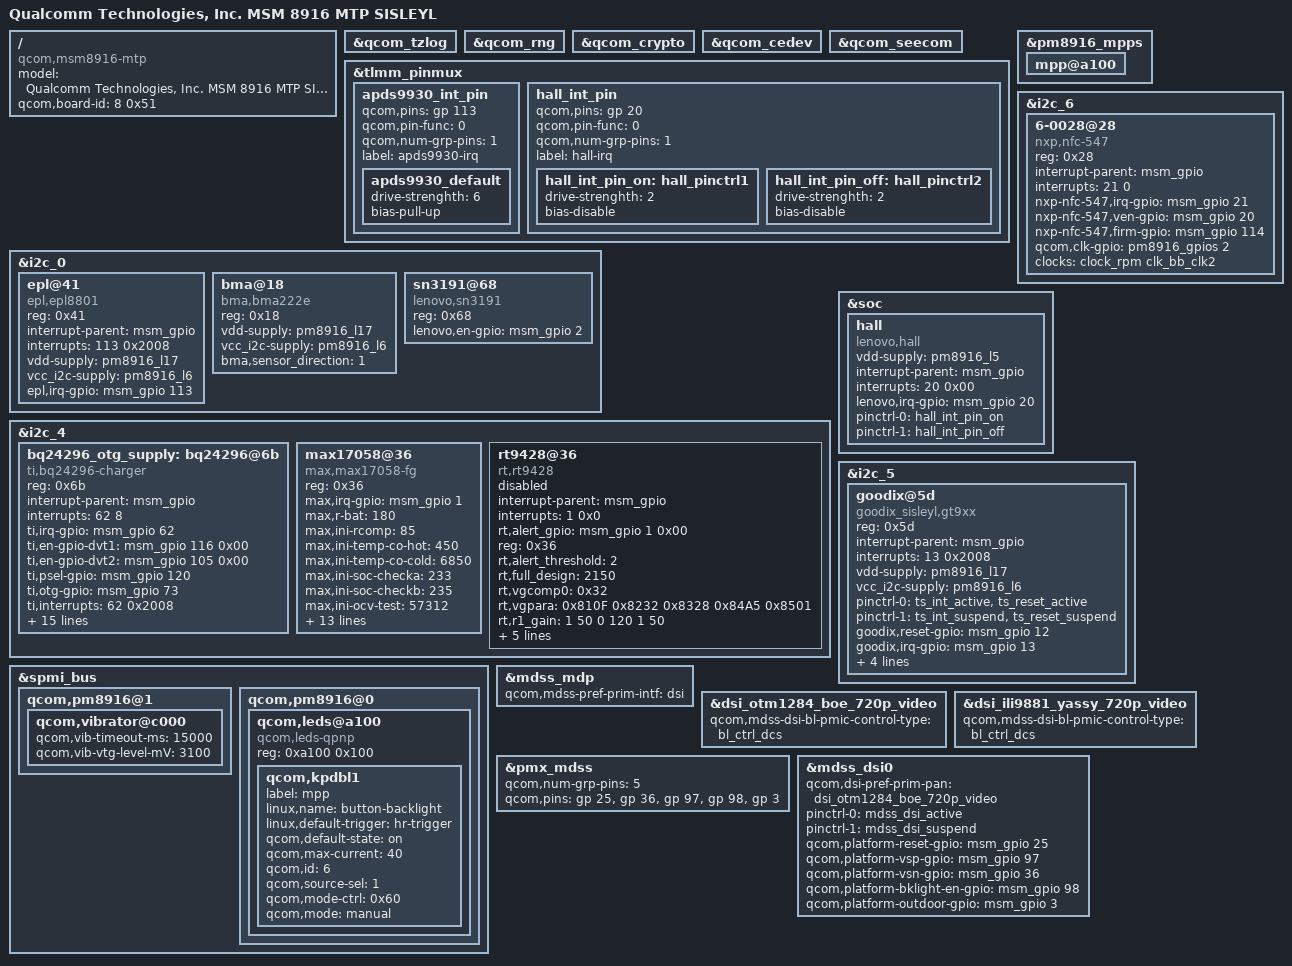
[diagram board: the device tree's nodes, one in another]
/* Copyright (c) 2014, The Linux Foundation. All rights reserved.
*
* This program is free software; you can redistribute it and/or modify
* it under the terms of the GNU General Public License version 2 and
* only version 2 as published by the Free Software Foundation.
*
* This program is distributed in the hope that it will be useful,
* but WITHOUT ANY WARRANTY; without even the implied warranty of
* MERCHANTABILITY or FITNESS FOR A PARTICULAR PURPOSE.  See the
* GNU General Public License for more details.
*/
/*
* sisleyl subtype_id is 0x51
* sisleyle subtype_id is 0x52
* sisleylr subtype_id is 0x53
* sisleylt subtype_id is 0x54
* sisleylw subtype_id is 0x55
*/
/dts-v1/;

/*#include "msm8916-mtp.dtsi"*/
#include "msm8916-mtp-sisleyl.dtsi"
#include "msm8916-memory.dtsi"

/ {
	model = "Qualcomm Technologies, Inc. MSM 8916 MTP SISLEYL";
	compatible = "qcom,msm8916-mtp", "qcom,msm8916", "qcom,mtp", "lenovo,sisleyl";
	qcom,board-id = <8 0x51>;
};

&qcom_tzlog {
	status = "okay";
};

&qcom_rng {
	status = "okay";
};

&qcom_crypto {
	status = "okay";
};

&qcom_cedev {
	status = "okay";
};

&qcom_seecom {
	status = "okay";
};

&tlmm_pinmux {
	apds9930_int_pin {
		qcom,pins = <&gp 113>;
		qcom,pin-func = <0>;
		qcom,num-grp-pins = <1>;
		label = "apds9930-irq";
		apds9930_default: apds9930_default {
			drive-strenghth = <6>;
			bias-pull-up;
		};
	};

	hall_int_pin {
		qcom,pins = <&gp 20>;
		qcom,pin-func = <0>;
		qcom,num-grp-pins = <1>;
		label = "hall-irq";
		hall_int_pin_on: hall_pinctrl1 {
			drive-strenghth = <2>;
			bias-disable;
		};
		hall_int_pin_off: hall_pinctrl2 {
			drive-strenghth = <2>;
			bias-disable;
		};
	};
};

&i2c_0 { /* BLSP1 QUP2 */
/*lenovo-sw molg 20140701 add begin*/
	epl@41 {
			compatible = "epl,epl8801";
			reg = <0x41>;
			interrupt-parent = <&msm_gpio>;
			interrupts = <113 0x2008>;
			vdd-supply = <&pm8916_l17>;
			vcc_i2c-supply = <&pm8916_l6>;
			epl,irq-gpio = <&msm_gpio 113 0x2008>;
	};
/*lenovo-sw molg 20140701 add end*/
/*lenovo-sw molg 20140428 add begin*/
	bma@18 {
			compatible = "bma,bma222e";
			reg = <0x18>;
			vdd-supply = <&pm8916_l17>;
			vcc_i2c-supply = <&pm8916_l6>;
/*lenovo-sw youwc1 add for g-sensor direction start*/
			bma,sensor_direction = <1>;
/*lenovo-sw youwc1 add for g-sensor direction end*/
        };
/*lenovo-sw molg 20140428 add end*/
	sn3191@68 {
			compatible = "lenovo,sn3191";
			reg = <0x68>;
			lenovo,en-gpio = <&msm_gpio 2 0x00>;
	};
};

/*lenovo add by jixu@lenovo.com begin, wangxf14 modify msm_gpio 38 --> gpio 2 for sdcard work */
&i2c_4 {


		bq24296_otg_supply: bq24296@6b {
			compatible = "ti,bq24296-charger";
			reg = <0x6b>;
			interrupt-parent = <&msm_gpio>;
			interrupts = <62 8>;
			ti,irq-gpio = <&msm_gpio 62 0x2008>;
			ti,en-gpio-dvt1 = <&msm_gpio 116 0x00>;
			ti,en-gpio-dvt2 = <&msm_gpio 105 0x00>;
			ti,psel-gpio = <&msm_gpio 120 0x00>;
			ti,otg-gpio = <&msm_gpio 73 0x00>;
			ti,interrupts = <62 0x2008>;
			ti,current-limit = <1000>;
			ti,chg-current = <1000>;
			ti,cv-vol = <4350>;
			ti,term-current = <256>;
			ti,chg-temp-protect-cur-0m = <0>;
			ti,chg-temp-protect-cur-10m = <600>;
			ti,chg-temp-protect-cur-45m = <1000>;
			ti,chg-temp-protect-cur-50m = <600>;
			ti,chg-temp-protect-cur-50p = <0>;
			ti,chg-temp-protect-vol-0m = <4350>;
			ti,chg-temp-protect-vol-10m = <4350>;
			ti,chg-temp-protect-vol-45m = <4350>;
			ti,chg-temp-protect-vol-50m = <4350>;
			ti,chg-temp-protect-vol-50p = <4350>;

                        regulator-name = "bq24296_otg_vreg";
        };

		max17058@36 {
			compatible = "max,max17058-fg";
			status = "ok";
			reg = <0x36>;
			max,irq-gpio = <&msm_gpio 1 0x2008>;
			max,r-bat = <180>;//need to calculate
			max,ini-rcomp = <85>;
			max,ini-temp-co-hot = <450>;//factor 1000
			max,ini-temp-co-cold = <6850>;//factor 1000
			max,ini-soc-checka = <233>;
			max,ini-soc-checkb = <235>;
			max,ini-ocv-test = <57312>;
			max,ini-bits = <19>;
			max,model-data = [A5 50 B6 E0 B8 F0 BB 10 
								BB E0 BC B0 BD 90 BE 80 
								BF A0 C0 F0 C3 A0 C5 C0 
								C8 70 CB 40 D0 70 D5 E0 
								01 60 22 00 20 00 3C 00 
								3C 80 33 20 3B A0 23 00 
								23 E0 11 60 19 E0 10 E0 
								0F 40 10 A0 0E 00 0E 00];
			max,ini-rcomp-2 = <85>;
			max,ini-temp-co-hot-2 = <450>;//factor 1000
			max,ini-temp-co-cold-2 = <6850>;//factor 1000
			max,ini-soc-checka-2 = <233>;
			max,ini-soc-checkb-2 = <235>;
			max,ini-ocv-test-2 = <57312>;
			max,ini-bits-2 = <19>;
			max,model-data-2 = [A5 50 B6 E0 B8 F0 BB 10 
								BB E0 BC B0 BD 90 BE 80 
								BF A0 C0 F0 C3 A0 C5 C0 
								C8 70 CB 40 D0 70 D5 E0 
								01 60 22 00 20 00 3C 00 
								3C 80 33 20 3B A0 23 00 
								23 E0 11 60 19 E0 10 E0 
								0F 40 10 A0 0E 00 0E 00];
			qcom,fg-vadc = <&pm8916_vadc>;
        };	

/*lenovo-sw weiweij added for rt9428*/	
		rt9428@36 {
			compatible = "rt,rt9428";
			status = "disabled";
			interrupt-parent = <&msm_gpio>;
			interrupts = <1 0x0>;
			rt,alert_gpio = <&msm_gpio 1 0x00>;
			reg = <0x36>;
			rt,alert_threshold = <2>;
			rt,full_design = <2150>;
			rt,vgcomp0 = <0x32>;
			rt,vgpara = <0x810F 0x8232 0x8328 0x84A5 0x8501>;
			rt,r1_gain = <1 50  0 120 1 50>;
			rt,r2_gain = <0 625 0 28   0 625>;
			rt,r3_gain = <1 120 0 20  1 120>;
			rt,r4_gain = <1 700 0 320 1 700>;
			rt,temp_base = <0 5 0 5 0 25 0 50>;
			rt,soc_comp = <0>;
		};
/*lenovo-sw weiweij added for rt9428 end*/
};

/* lenovo-sw wangxf14 get rid of disable sdcard config, enable sdcard */

&pm8916_mpps{
    mpp@a100 {
        status = "ok";
    };
};

/*lenovo add by jixu@lenovo.com end*/


&i2c_6 { /* BLSP1 QUP6 */
	6-0028@28 {
		compatible = "nxp,nfc-547";
		reg = <0x28>;
          /*
		qcom,irq-gpio = <&msm_gpio 21 0x00>;
		qcom,dis-gpio = <&msm_gpio 20 0x00>;
		qcom,clk-src = "BBCLK2";
		qcom,clk-en-gpio = <&msm_gpio 0 0x00>;
          */
		interrupt-parent = <&msm_gpio>;
		interrupts = <21 0>;
          /*
		interrupt-names = "nfc_irq";
		pinctrl-names = "nfc_active","nfc_suspend";
		pinctrl-0 = <&nfc_int_active &nfc_disable_active>;
		pinctrl-1 = <&nfc_int_suspend &nfc_disable_suspend>;
		*/
		nxp-nfc-547,irq-gpio = <&msm_gpio 21 0x00>;
		nxp-nfc-547,ven-gpio = <&msm_gpio 20 0x00>;
		nxp-nfc-547,firm-gpio = <&msm_gpio 114 0x00>;
		qcom,clk-gpio = <&pm8916_gpios 2 0>;
		clocks = <&clock_rpm clk_bb_clk2>;
		clock-names = "nfc_clk";
	};
};

&spmi_bus {
	qcom,pm8916@1 {
		qcom,vibrator@c000 {
			status = "okay";
			qcom,vib-timeout-ms = <15000>;
			qcom,vib-vtg-level-mV = <3100>;
		};
	};
/*lenovo add by jixu@lenovo.com begin*/
	qcom,pm8916@0 {
		qcom,leds@a100 {
		compatible = "qcom,leds-qpnp";
		reg = <0xa100 0x100>;
		status = "ok";
                qcom,kpdbl1 {
			label = "mpp";
			linux,name = "button-backlight";
			linux,default-trigger = "hr-trigger";
			qcom,default-state = "on";
			qcom,max-current = <40>;
			qcom,id = <6>;
			qcom,source-sel = <1>;
			qcom,mode-ctrl = <0x60>;
			qcom,mode = "manual";
                };
	    };
	};
/*lenovo add by jixu@lenovo.com end*/
};

/* lenovo-sw yexh1, add for usb driver current setting and otg function, 2014-04-16 add begin */
/*lenovo-sw weiweij removed for internel linear charging*/
/*&usb_otg{          
        qcom,hsusb-otg-phy-init-seq = <0x44 0x80 0x6F 0x81 0x20 0x82 0x13 0x83 0xffffffff>;
	qcom,hsusb-otg-mode = <3>;
	qcom,usbid-gpio = <&msm_gpio 110 0>;
	pinctrl-names = "default";
	pinctrl-0 = <&usbid_default>;
	vbus_otg-supply = <&bq24296_otg_supply>; //<&pm8916_l16>; // <&smb1360_otg_supply>; //<&pm8916_l16>; //
};*/
/* lenovo-sw yexh1 end */

&soc {
	hall {
		status = "okay";
		compatible = "lenovo,hall";
		vdd-supply = <&pm8916_l5>;
		interrupt-parent = <&msm_gpio>;
		interrupts = <20 0x00>;
		lenovo,irq-gpio = <&msm_gpio 20 0x00>;
		/* pinctrl-states = "default"; */
		pinctrl-names = "hall_pinctrl_on", "hall_pinctrl_off";
		pinctrl-0 = <&hall_int_pin_on>;
		pinctrl-1 = <&hall_int_pin_off>;
	};
};

/* lenovo-sw wengjun1, 2014-04-18 add begin */
&i2c_5 { /* BLSP1 QUP5 */
/* lenovo-sw lixh10, 2014-06-19 add begin */
		goodix@5d {
			compatible = "goodix_sisleyl,gt9xx";
			reg = <0x5d>;
			interrupt-parent = <&msm_gpio>;
			interrupts = <13 0x2008>;
			vdd-supply = <&pm8916_l17>;
			vcc_i2c-supply = <&pm8916_l6>;
			/* pins used by touchscreen */
			pinctrl-names = "pmx_ts_active","pmx_ts_suspend";
			pinctrl-0 = <&ts_int_active &ts_reset_active>;
			pinctrl-1 = <&ts_int_suspend &ts_reset_suspend>;
			goodix,reset-gpio = <&msm_gpio 12 0x0>;
			goodix,irq-gpio = <&msm_gpio 13 0x2008>;
			//goodix,ldo-en-gpio = <&msmgpio 15 0x00>;
			goodix,panel-coords = <0 0 720 1280>;
			goodix,display-coords = <0 0 720 1280>;
			goodix,button-map= <158 102 139>;
			goodix,family-id = <0x0>;
			/*
			goodix,cfg-data = [
		41 1C 02 C0 03 05 31 07 03 08
		14 08 41 32 03 04 00 00 00 00
		00 00 00 18 1A 1E 14 8B 2B 0C
		1C 1E 8C 20 00 00 00 9A 03 2D
		00 00 00 00 00 00 00 00 00 22
		00 4B FA 94 85 02 05 00 00 E5
		1B 1A ED 1C 1C 3C 1F 1E 3C 1F
		24 08 27 1F 00 00 10 38 58 00
		67 60 45 FF FF 07 00 00 00 00
		00 01 06 14 0C 16 E8 03 02 00
		00 03 28 28 E5 00 23 23 00 00
		00 00 02 04 06 08 0A 0C 0E 10
		12 14 16 18 FF FF FF FF FF FF
		FF FF FF FF FF FF FF FF FF FF
		FF FF 00 02 04 06 08 0A 0C 0F
		10 12 13 16 18 1C 1D 1E 1F 20
		21 22 24 26 FF FF FF FF FF FF
		FF FF FF FF FF FF FF FF FF FF
		FF FF FF FF 90 01];
		*/
		};
/* lenovo-sw lixh10, 2014-06-19 add end */
};

/* add bylenovo-sw2 houdz1 20140418 begin*/
#include "lenovo-boe-dsi-panel-otm1284-720p-video.dtsi"
#include "lenovo-yassy-dsi-panel-ili9881-720p-video.dtsi"

&mdss_mdp {
	qcom,mdss-pref-prim-intf = "dsi";
};
			
			


&dsi_otm1284_boe_720p_video{
	qcom,mdss-dsi-bl-pmic-control-type = "bl_ctrl_dcs";
};

&dsi_ili9881_yassy_720p_video{
	qcom,mdss-dsi-bl-pmic-control-type = "bl_ctrl_dcs";
};

&pmx_mdss {
	qcom,num-grp-pins = <5>;
	qcom,pins = <&gp 25>, <&gp 36>,<&gp 97>, <&gp 98>, <&gp 3>;
};
			
&mdss_dsi0 {
	qcom,dsi-pref-prim-pan = <&dsi_otm1284_boe_720p_video>;
	pinctrl-names = "mdss_default", "mdss_sleep";
	pinctrl-0 = <&mdss_dsi_active>;
	pinctrl-1 = <&mdss_dsi_suspend>;
			
	qcom,platform-reset-gpio = <&msm_gpio 25 0>;
			
	qcom,platform-vsp-gpio = <&msm_gpio 97 0>;
	qcom,platform-vsn-gpio = <&msm_gpio 36 0>; 
	qcom,platform-bklight-en-gpio = <&msm_gpio 98 0>;

	qcom,platform-outdoor-gpio = <&msm_gpio 3 0>;
};

/* add bylenovo-sw2 houdz1 20140418 end*/

			
